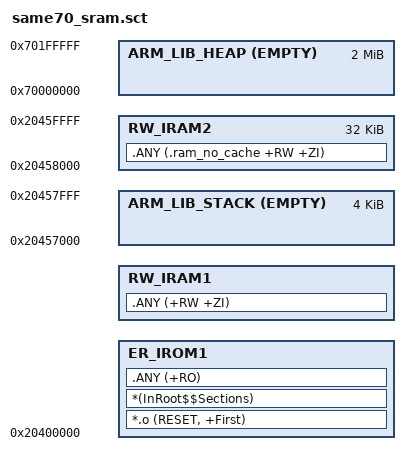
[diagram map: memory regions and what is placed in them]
;****************************************************************
;* SAME70 linker scatter file (running code from internal SRAM) *
;****************************************************************

LR_IROM1 0x20400000 0x60000
{
   ER_IROM1 0x20400000
   {
      *.o (RESET, +First)
      *(InRoot$$Sections)
      .ANY (+RO)
   }
   
   RW_IRAM1 +0
   { 
      .ANY (+RW +ZI)
   }
   
   ScatterAssert((ImageLength(ER_IROM1) + ImageLength(RW_IRAM1)) < 0x57000)
   
   ARM_LIB_STACK 0x20458000 EMPTY -0x1000
   {
   }
   
   RW_IRAM2 0x20458000 0x8000
   {
      .ANY (.ram_no_cache +RW +ZI)
   }
   
   ARM_LIB_HEAP 0x70000000 EMPTY 0x200000
   {
   }
}
